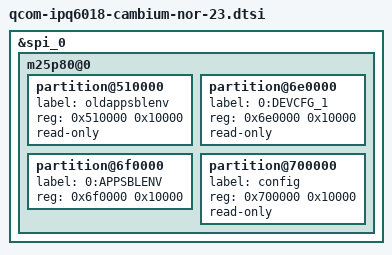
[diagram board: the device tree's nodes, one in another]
// SPDX-License-Identifier: (GPL-2.0+ OR BSD-3-Clause)
/*
 * Cambium AP-CP01 boards with the 23-entry NOR map: XV2-2T1 and XE3-4
 *
 * qcom-ipq6018-cambium-xv2-2t.dtsi carries the XV2-2T0's 16-partition NOR
 * table. The XV2-2T1 and the XE3-4 do not share it: their MIBIB has 23
 * entries where the 2T0's has 20, and the vendor moved the U-Boot
 * environment. 0x510000 still exists but is a stale copy the bootloader no
 * longer reads (its contents date from before the unit shipped), and stock's
 * own fw_env.config points at 0x6f0000, with 0:DEVCFG_1 at 0x6e0000 and
 * config at 0x700000 around it. The two boards' MIBIB partitions are
 * byte-identical, so they share these overrides; include this file after
 * the 2T dtsi.
 *
 * Declaring the inherited offset would make fw_setenv write the dead copy:
 * the write would succeed, a readback would agree with itself, and U-Boot
 * would never see the new bootcmd - a silent non-install rather than a
 * visible failure. Verified against each unit's /sys/class/mtd offsets and
 * a full 16 MB flash dump.
 *
 * Copyright (c) 2019-2021 The Linux Foundation. All rights reserved.
 */

&spi_0 {
	m25p80@0 {
		partition@510000 {
			label = "oldappsblenv";
			reg = <0x510000 0x10000>;
			read-only;
		};

		partition@6e0000 {
			label = "0:DEVCFG_1";
			reg = <0x6e0000 0x10000>;
			read-only;
		};

		partition@6f0000 {
			label = "0:APPSBLENV";
			reg = <0x6f0000 0x10000>;
		};

		partition@700000 {
			label = "config";
			reg = <0x700000 0x10000>;
			read-only;
		};
	};
};
